# ATSAMA5D36 register map
Vendor: Microchip Technology; Series: SAMA5D3; File version: 0
Registers are 32-bit, read-write, reset 0x0 unless marked. A register's access mark holds for its fields unless they carry their own. Offsets are from the block's base; [hi:lo] are bit positions; {n}, {i} and the like mark numbered series; 'fields as' and 'values as' point back to an identical list.

## AXIMX — AXI Matrix
Base 0x00800000
0x00 REMAP wo — AXI Matrix Remap Register
  [0] REMAP0 — Remap State 0

## BSC — Boot Sequence Controller
Base 0xFFFFFE54
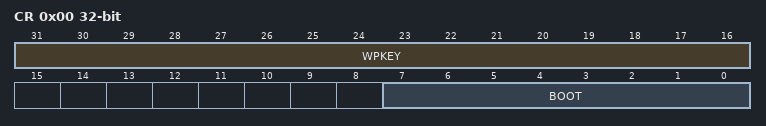
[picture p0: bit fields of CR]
0x00 CR — Boot Sequence Controller Configuration Register
  [31:16] WPKEY — Write Protection Key (Write-only)
    0x6683=PASSWD (Writing any other value in this field aborts the write operation of the BOOT field.Always reads as 0.)
  [7:0] BOOT — Boot Media Sequence

## FUSE — Fuse Controller
Base 0xFFFFE400
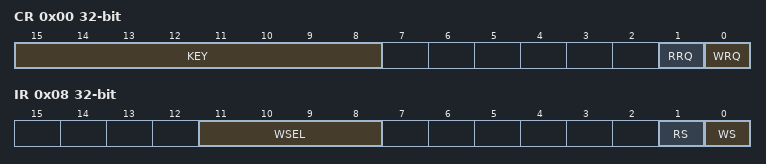
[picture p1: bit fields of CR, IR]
0x00 CR wo — Fuse Control Register
  [15:8] KEY — Key code
    251=VALID (Writing any other value in this field aborts the write operation of the WRQ and RRQ bits.Always reads as 0.)
  [1] RRQ — Read Request
  [0] WRQ — Write Request
0x04 MR wo — Fuse Mode Register
  [0] MSK — Mask Fuse Status Registers
0x08 IR — Fuse Index Register
  [11:8] WSEL — Word Selection
  [1] RS — Read Status
  [0] WS — Write Status
0x0C DR — Fuse Data Register
  [31:0] DATA — Data to Program
{0x10+4i} SR[{i}] (i=0..7) ro — Fuse Status Register
  [31:0] FUSE — Fuse Status

## GPBR — General Purpose Backup Registers
Base 0xFFFFFE60
{0x0+4i} SYS_GPBR[{i}] (i=0..3) — General Purpose Backup Register
  [31:0] GPBR_VALUE — Value of GPBR x

## PIT — Periodic Interval Timer
Base 0xFFFFFE30
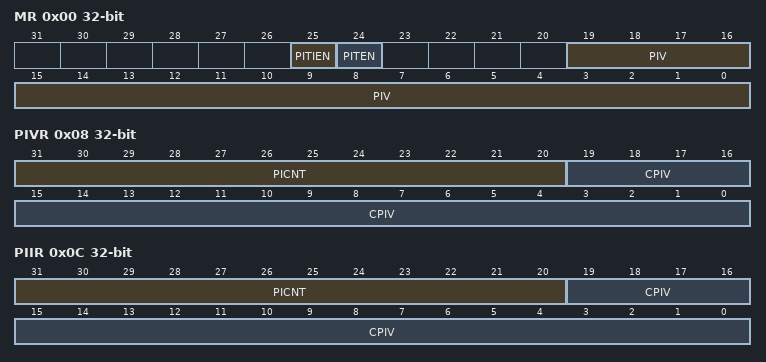
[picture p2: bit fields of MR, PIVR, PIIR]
0x00 MR — Mode Register
  [25] PITIEN — Periodic Interval Timer Interrupt Enable
  [24] PITEN — Period Interval Timer Enabled
  [19:0] PIV — Periodic Interval Value
0x04 SR ro — Status Register
  [0] PITS — Periodic Interval Timer Status
0x08 PIVR ro — Periodic Interval Value Register
  [31:20] PICNT — Periodic Interval Counter
  [19:0] CPIV — Current Periodic Interval Value
0x0C PIIR ro — Periodic Interval Image Register
  fields as PIVR

## RSTC — Reset Controller
Base 0xFFFFFE00
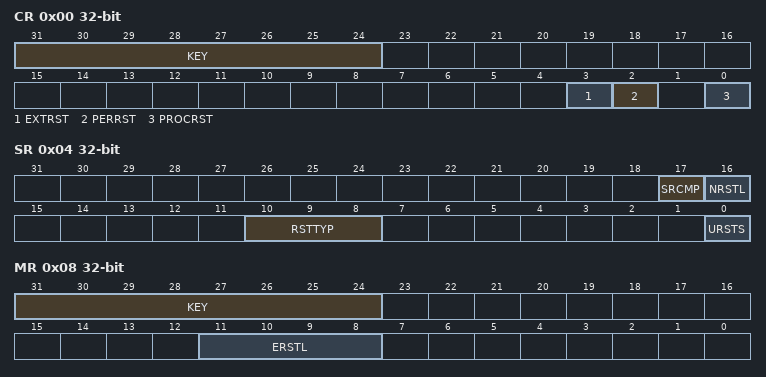
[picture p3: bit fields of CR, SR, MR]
0x00 CR wo — Control Register
  [31:24] KEY — Write Access Password
    165=PASSWD (Writing any other value in this field aborts the write operation.Always reads as 0.)
  [3] EXTRST — External Reset
  [2] PERRST — Peripheral Reset
  [0] PROCRST — Processor Reset
0x04 SR ro — Status Register
  [17] SRCMP — Software Reset Command in Progress
  [16] NRSTL — NRST Pin Level
  [10:8] RSTTYP — Reset Type
    0=GENERAL_RST (Both VDDCORE and VDDBU rising); 1=WKUP_RST (VDDCORE rising); 2=WDT_RST (Watchdog fault occurred); 3=SOFT_RST (Processor reset required by the software); 4=USER_RST (NRST pin detected low)
  [0] URSTS — User Reset Status
0x08 MR — Mode Register
  [31:24] KEY — Write Access Password
    values as CR.KEY
  [11:8] ERSTL — External Reset Length

## RTC — Real-time Clock
Base 0xFFFFFEB0
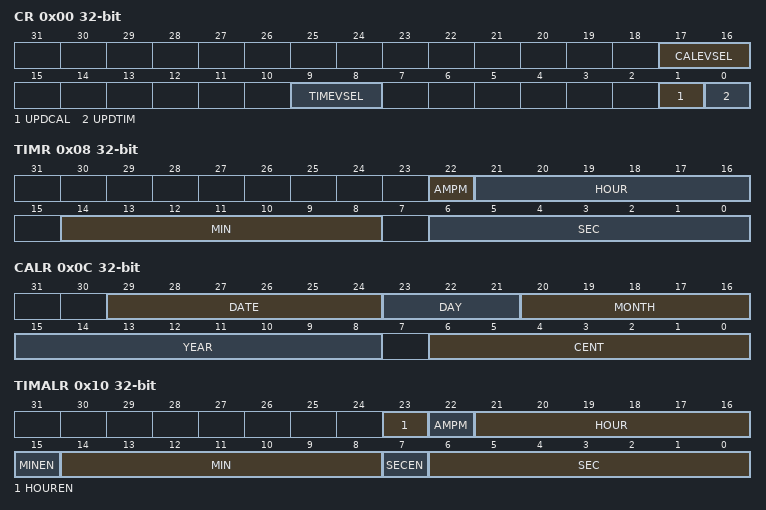
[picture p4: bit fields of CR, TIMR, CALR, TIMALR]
0x00 CR — Control Register
  [17:16] CALEVSEL — Calendar Event Selection
    0=WEEK (Week change (every Monday at time 00:00:00)); 1=MONTH (Month change (every 01 of each month at time 00:00:00)); 2=YEAR (Year change (every January 1 at time 00:00:00))
  [9:8] TIMEVSEL — Time Event Selection
    0=MINUTE (Minute change); 1=HOUR (Hour change); 2=MIDNIGHT (Every day at midnight); 3=NOON (Every day at noon)
  [1] UPDCAL — Update Request Calendar Register
  [0] UPDTIM — Update Request Time Register
0x04 MR — Mode Register
  [0] HRMOD — 12-/24-hour Mode
0x08 TIMR — Time Register
  [22] AMPM — Ante Meridiem Post Meridiem Indicator
  [21:16] HOUR — Current Hour
  [14:8] MIN — Current Minute
  [6:0] SEC — Current Second
0x0C CALR — Calendar Register
  [29:24] DATE — Current Day in Current Month
  [23:21] DAY — Current Day in Current Week
  [20:16] MONTH — Current Month
  [15:8] YEAR — Current Year
  [6:0] CENT — Current Century
0x10 TIMALR — Time Alarm Register
  [23] HOUREN — Hour Alarm Enable
  [22] AMPM — AM/PM Indicator
  [21:16] HOUR — Hour Alarm
  [15] MINEN — Minute Alarm Enable
  [14:8] MIN — Minute Alarm
  [7] SECEN — Second Alarm Enable
  [6:0] SEC — Second Alarm
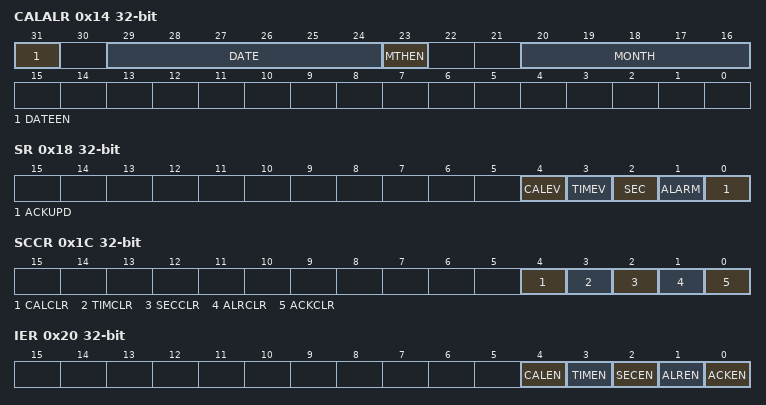
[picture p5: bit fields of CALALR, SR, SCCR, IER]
0x14 CALALR — Calendar Alarm Register
  [31] DATEEN — Date Alarm Enable
  [29:24] DATE — Date Alarm
  [23] MTHEN — Month Alarm Enable
  [20:16] MONTH — Month Alarm
0x18 SR ro — Status Register
  [4] CALEV — Calendar Event
    0=NO_CALEVENT (No calendar event has occurred since the last clear.); 1=CALEVENT (At least one calendar event has occurred since the last clear.)
  [3] TIMEV — Time Event
    0=NO_TIMEVENT (No time event has occurred since the last clear.); 1=TIMEVENT (At least one time event has occurred since the last clear.)
  [2] SEC — Second Event
    0=NO_SECEVENT (No second event has occurred since the last clear.); 1=SECEVENT (At least one second event has occurred since the last clear.)
  [1] ALARM — Alarm Flag
    0=NO_ALARMEVENT (No alarm matching condition occurred.); 1=ALARMEVENT (An alarm matching condition has occurred.)
  [0] ACKUPD — Acknowledge for Update
    0=FREERUN (Time and calendar registers cannot be updated.); 1=UPDATE (Time and calendar registers can be updated.)
0x1C SCCR wo — Status Clear Command Register
  [4] CALCLR — Calendar Clear
  [3] TIMCLR — Time Clear
  [2] SECCLR — Second Clear
  [1] ALRCLR — Alarm Clear
  [0] ACKCLR — Acknowledge Clear
0x20 IER wo — Interrupt Enable Register
  [4] CALEN — Calendar Event Interrupt Enable
  [3] TIMEN — Time Event Interrupt Enable
  [2] SECEN — Second Event Interrupt Enable
  [1] ALREN — Alarm Interrupt Enable
  [0] ACKEN — Acknowledge Update Interrupt Enable
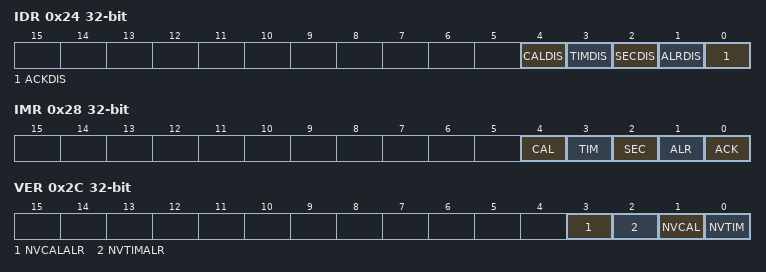
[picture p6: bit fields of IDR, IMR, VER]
0x24 IDR wo — Interrupt Disable Register
  [4] CALDIS — Calendar Event Interrupt Disable
  [3] TIMDIS — Time Event Interrupt Disable
  [2] SECDIS — Second Event Interrupt Disable
  [1] ALRDIS — Alarm Interrupt Disable
  [0] ACKDIS — Acknowledge Update Interrupt Disable
0x28 IMR ro — Interrupt Mask Register
  [4] CAL — Calendar Event Interrupt Mask
  [3] TIM — Time Event Interrupt Mask
  [2] SEC — Second Event Interrupt Mask
  [1] ALR — Alarm Interrupt Mask
  [0] ACK — Acknowledge Update Interrupt Mask
0x2C VER ro — Valid Entry Register
  [3] NVCALALR — Non-valid Calendar Alarm
  [2] NVTIMALR — Non-valid Time Alarm
  [1] NVCAL — Non-valid Calendar
  [0] NVTIM — Non-valid Time
